# liliumFP1_secure register map
Vendor: Nordic Semiconductor; Series: liliumFP1; File version: 1
CPU: CM33 r0p4, little endian, MPU, FPU, 3 interrupt priority bits, 480 interrupts
Registers are 32-bit, read-write, reset 0x0 unless marked. A register's access mark holds for its fields unless they carry their own. Offsets are from the block's base; [hi:lo] are bit positions; lines under a group give offsets from that group; {n}, {i} and the like mark numbered series; 'fields as' and 'values as' point back to an identical list.

## RESETINFO_S — RESETINFO
Base 0x5101E000; alternate view of LRCCONF010_S
0x4C0 RESTOREVALID write-1-clears — Valid restore image is present in RAM.
  [0] RESTOREVALID
    0=NotPreset (Not present); 1=Present
0x4C4 MASKLOCKUP — Mask CPU lockup signal.
  [0] MASK — Mask lockup signal
    0=NotMask (Do not mask lockup signal); 1=Mask lockup signal

## BELLBOARD_NS — BELLBOARD APB registers 0
Base 0x4F099000
Same registers: BELLBOARD_S 0x5F099000
{0x0+4i} TASKS_TRIGGER[{i}] (i=0..31) wo — Description collection: Task TRIGGER[n]
  [0] TASKS_TRIGGER — Task TRIGGER[n]
    1=Trigger task
{0x100+4i} EVENTS_TRIGGERED[{i}] (i=0..31) — Description collection: Event TRIGGERED[n]
  [0] EVENTS_TRIGGERED — Event TRIGGERED[n]
    0=NotGenerated (Event not generated); 1=Generated (Event generated)
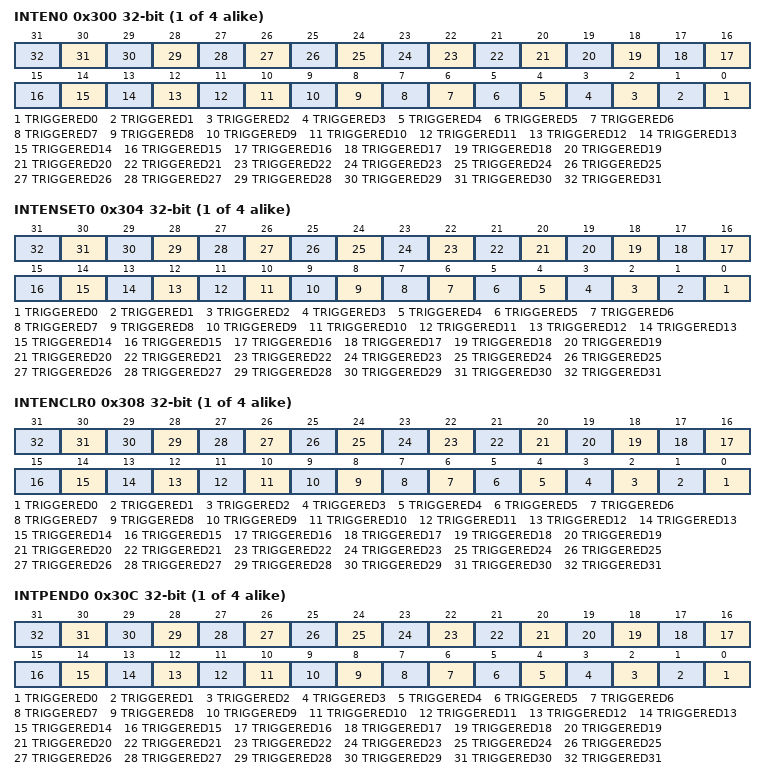
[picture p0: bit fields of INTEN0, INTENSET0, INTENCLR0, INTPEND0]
{0x300+0x10*i} INTEN{i} (i=0..3) — Enable or disable interrupt
  [all] fields
    0=Disabled; 1=Enabled
  [n] TRIGGERED{n} (n=0..31) — Enable or disable interrupt for event TRIGGERED[{n}]
{0x304+0x10*i} INTENSET{i} (i=0..3) — Enable interrupt
  [all] fields
    on read: 0=Disabled (Read: Disabled); 1=Enabled (Read: Enabled) | on write: 1=Set (Enable)
  [n] TRIGGERED{n} (n=0..31) — Write '1' to enable interrupt for event TRIGGERED[{n}]
{0x308+0x10*i} INTENCLR{i} (i=0..3) — Disable interrupt
  [all] fields
    on read: 0=Disabled (Read: Disabled); 1=Enabled (Read: Enabled) | on write: 1=Clear (Disable)
  [n] TRIGGERED{n} (n=0..31) — Write '1' to disable interrupt for event TRIGGERED[{n}]
{0x30C+0x10*i} INTPEND{i} ro (i=0..3) — Pending interrupts
  [all] fields
    on read: 0=NotPending (Read: Not pending); 1=Pending (Read: Pending)
  [n] TRIGGERED{n} (n=0..31) — Read pending status of interrupt for event TRIGGERED[{n}]

## GLOBAL_TDDCONF_NS — TDDCONF 0
Base 0xBF001000
Same registers: GLOBAL_TDDCONF_S 0xBF001000 (alternate view of GLOBAL_TDDCONF_NS)
0x400 SYSPWRUPREQ — System power-up request
  [0] ACTIVE — Activate power-up request
    0=NotActive (Power-up request not active); 1=Active (Power-up request active)
0x404 DBGPWRUPREQ — Debug power-up request
  fields as SYSPWRUPREQ
0x408 TRACEPORTSPEED — Trace port trace clock speed
  [1:0] SPEED — Trace clock speed
    0=Speed100MHz; 1=Speed50MHz; 2=Speed25MHz; 3=Speed12500KHz (Speed 12.5MHz)
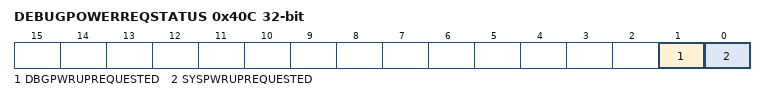
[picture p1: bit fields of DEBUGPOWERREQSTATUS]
0x40C DEBUGPOWERREQSTATUS ro — Combined effective system status of both SWJ-DP and TDDCONF registers originated power requests
  [1] DBGPWRUPREQUESTED — Debug domain powerup request status
    0=NoPowerReq (Power not requested); 1=Power requested
  [0] SYSPWRUPREQUESTED — System powerup request status
    0=NoPowerReq (Power not requested); 1=Power requested

## CTRLAP_S — Control access port
Base 0xBF015000
0x100 EVENTS_RXREADY — The RXSTATUS is changed to DataPending
  [0] EVENTS_RXREADY
    0=NotGenerated (Event not generated); 1=Generated (Event generated)
0x104 EVENTS_TXDONE — The TXSTATUS is changed to NoDataPending
  [0] EVENTS_TXDONE
    values as EVENTS_RXREADY.EVENTS_RXREADY
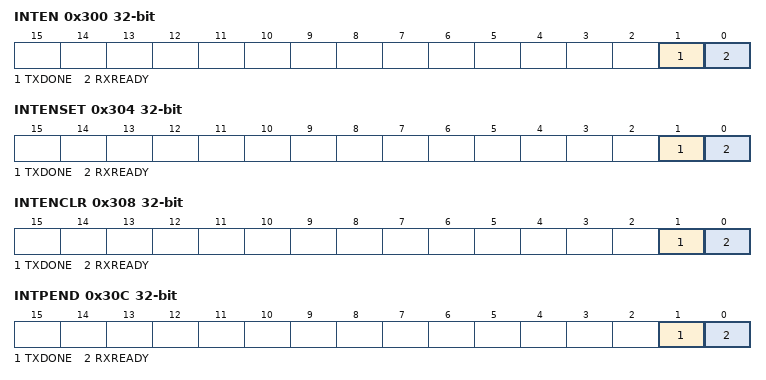
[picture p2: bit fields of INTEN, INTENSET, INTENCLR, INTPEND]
0x300 INTEN — Enable or disable interrupt
  [1] TXDONE — Enable or disable interrupt for event TXDONE
    0=Disabled; 1=Enabled
  [0] RXREADY — Enable or disable interrupt for event RXREADY
    0=Disabled; 1=Enabled
0x304 INTENSET — Enable interrupt
  [1] TXDONE — Write '1' to enable interrupt for event TXDONE
    on read: 0=Disabled (Read: Disabled); 1=Enabled (Read: Enabled) | on write: 1=Set (Enable)
  [0] RXREADY — Write '1' to enable interrupt for event RXREADY
    values as TXDONE
0x308 INTENCLR — Disable interrupt
  [1] TXDONE — Write '1' to disable interrupt for event TXDONE
    on read: 0=Disabled (Read: Disabled); 1=Enabled (Read: Enabled) | on write: 1=Clear (Disable)
  [0] RXREADY — Write '1' to disable interrupt for event RXREADY
    values as TXDONE
0x30C INTPEND ro — Pending interrupts
  [1] TXDONE — Read pending status of interrupt for event TXDONE
    on read: 0=NotPending (Read: Not pending); 1=Pending (Read: Pending)
  [0] RXREADY — Read pending status of interrupt for event RXREADY
    values as TXDONE
0x400 MAILBOX group — Unspecified
  0x00 RXDATA ro — Data sent from the debugger to the CPU
    [31:0] RXDATA — Data received from debugger
  0x04 RXSTATUS ro — Status to indicate if data sent from the debugger to the CPU has been read
    [0] RXSTATUS — Status of data in register RXDATA
      0=No data pending in register RXDATA; 1=Data pending in register RXDATA
  0x80 TXDATA — Data sent from the CPU to the debugger
    [31:0] TXDATA — Data sent to debugger
  0x84 TXSTATUS ro — Status to indicate if data sent from the CPU to the debugger has been read
    [0] TXSTATUS — Status of data in register TXDATA
      0=No data pending in register TXDATA; 1=Data pending in register TXDATA
  0x88 BOOTMODE ro — Secure domain boot mode.
    [0] MODE
      0=Normal mode of operation; 1=ROM operation mode
0x500 INFO group — Unspecified
  0x00 PARTNO — Part number of the device
    [11:0] PARTNO — Part number
  0x04 HWREVISION — Hardware Revision of the device
    [3:0] ID — Part Variant
  0x08 READY reset 0x1 — The INFO registers ready status.
    [0] READY — Ready status.
      0=Ready; 1=NotReady (Not reday)
  0x0C BOOTSTATUS
    [31:0] VAL — Value
